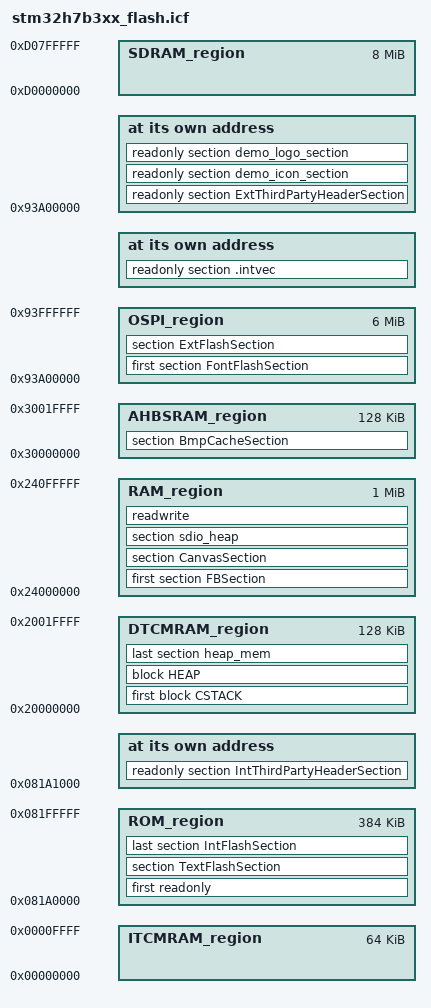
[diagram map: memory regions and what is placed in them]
/*###ICF### Section handled by ICF editor, don't touch! ****/
/*-Editor annotation file-*/
/* IcfEditorFile="$TOOLKIT_DIR$\config\ide\IcfEditor\cortex_v1_0.xml" */
/*-Specials-*/
define symbol __ICFEDIT_intvec_start__ = __C_START_ADDR;  /* 0x081A0000 */
/*-Memory Regions-*/
define symbol __ICFEDIT_region_ROM_start__ = 0x081A0000;
define symbol __ICFEDIT_region_ROM_end__   = 0x081FFFFF;  /* 384 Kbytes */

/*-Internal RAM Memory Regions-*/
define symbol __ICFEDIT_region_ITCMRAM_start__ = 0x00000000;
define symbol __ICFEDIT_region_ITCMRAM_end__   = 0x0000FFFF;  /*   64 Kbytes */
define symbol __ICFEDIT_region_DTCMRAM_start__ = 0x20000000;
define symbol __ICFEDIT_region_DTCMRAM_end__   = 0x2001FFFF;  /*  128 Kbytes */
define symbol __ICFEDIT_region_RAM_start__     = 0x24000000;
define symbol __ICFEDIT_region_RAM_end__       = 0x240FFFFF;  /* 1024 Kbytes */
define symbol __ICFEDIT_region_SDRAM_start__   = 0xD0000000;
define symbol __ICFEDIT_region_SDRAM_end__     = 0xD07FFFFF;  /*    8 Mbytes */
define symbol __ICFEDIT_region_AHBSRAM_start__ = 0x30000000;
define symbol __ICFEDIT_region_AHBSRAM_end__   = 0x3001FFFF;  /*    128 Kbytes */

/*-Quad-SPI Memory Regions-*/
define symbol __ICFEDIT_region_OSPI_start__ = 0x93A00000;
define symbol __ICFEDIT_region_OSPI_end__   = 0x93FFFFFF;  /*  3 Mbytes external flash */

/*-Sizes-*/
define symbol __ICFEDIT_size_cstack__ = 0x2000;  /* 4 Kb */
define symbol __ICFEDIT_size_heap__   = 0x2000;  /* 4 Kb */
/**** End of ICF editor section. ###ICF###*/

define memory mem with size = 4G;
define region ROM_region        = mem:[from __ICFEDIT_region_ROM_start__        to __ICFEDIT_region_ROM_end__];
define region ITCMRAM_region    = mem:[from __ICFEDIT_region_ITCMRAM_start__    to __ICFEDIT_region_ITCMRAM_end__];
define region DTCMRAM_region    = mem:[from __ICFEDIT_region_DTCMRAM_start__    to __ICFEDIT_region_DTCMRAM_end__];
define region RAM_region        = mem:[from __ICFEDIT_region_RAM_start__        to __ICFEDIT_region_RAM_end__];
define region SDRAM_region      = mem:[from __ICFEDIT_region_SDRAM_start__      to __ICFEDIT_region_SDRAM_end__];
define region AHBSRAM_region    = mem:[from __ICFEDIT_region_AHBSRAM_start__    to __ICFEDIT_region_AHBSRAM_end__];

define region OSPI_region  = mem:[from __ICFEDIT_region_OSPI_start__  to __ICFEDIT_region_OSPI_end__];

define block CSTACK       with alignment = 8, size = __ICFEDIT_size_cstack__    { };
define block HEAP         with alignment = 8, size = __ICFEDIT_size_heap__      { };

/*-Third Party Demonstration Headers-*/
define symbol __thp_int_header_start__ = __ICFEDIT_region_ROM_start__ + 0x1000;
define symbol __thp_ext_header_start__ = __ICFEDIT_region_OSPI_start__;

initialize by copy { readwrite };
do not initialize  { section .noinit };

place at address mem:__ICFEDIT_intvec_start__ { readonly section .intvec };

/*-Third Party headers Memory Placement-*/
place at address mem:__thp_int_header_start__   { readonly section IntThirdPartyHeaderSection };
place at address mem:__thp_ext_header_start__   { readonly section ExtThirdPartyHeaderSection, readonly section demo_icon_section, readonly section demo_logo_section };

place in DTCMRAM_region     { first block CSTACK, block HEAP, last section heap_mem};
place in RAM_region         { first section FBSection, section CanvasSection, section sdio_heap, readwrite};
place in ROM_region         { first readonly, section TextFlashSection, last section IntFlashSection };
place in SDRAM_region       { };
place in OSPI_region        { first section FontFlashSection, section ExtFlashSection };
place in AHBSRAM_region     {section BmpCacheSection};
